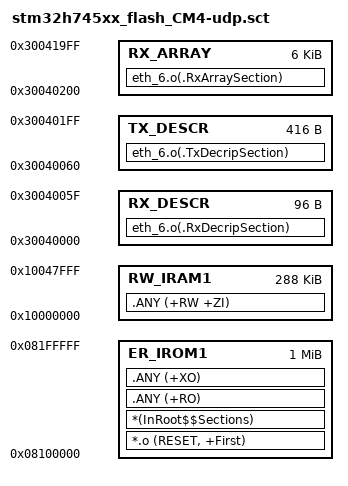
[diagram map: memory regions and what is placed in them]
; *************************************************************
; *** Scatter-Loading Description File generated by uVision ***
; *************************************************************

LR_IROM1 0x08100000 0x00100000  {    ; load region size_region
  ER_IROM1 0x08100000 0x00100000  {  ; load address = execution address
   *.o (RESET, +First)
   *(InRoot$$Sections)
   .ANY (+RO)
   .ANY (+XO)
  }
  RX_DESCR	0x30040000 0x00000060 {
  	eth_6.o(.RxDecripSection)
  }
  TX_DESCR	0x30040060 0x000001A0 {
  	eth_6.o(.TxDecripSection)
  }
  RX_ARRAY 	0x30040200 0x00001800 {
  	eth_6.o(.RxArraySection)
  }
  RW_IRAM1 0x10000000 0x00048000  {  ; RW data
   .ANY (+RW +ZI)
  }
}
